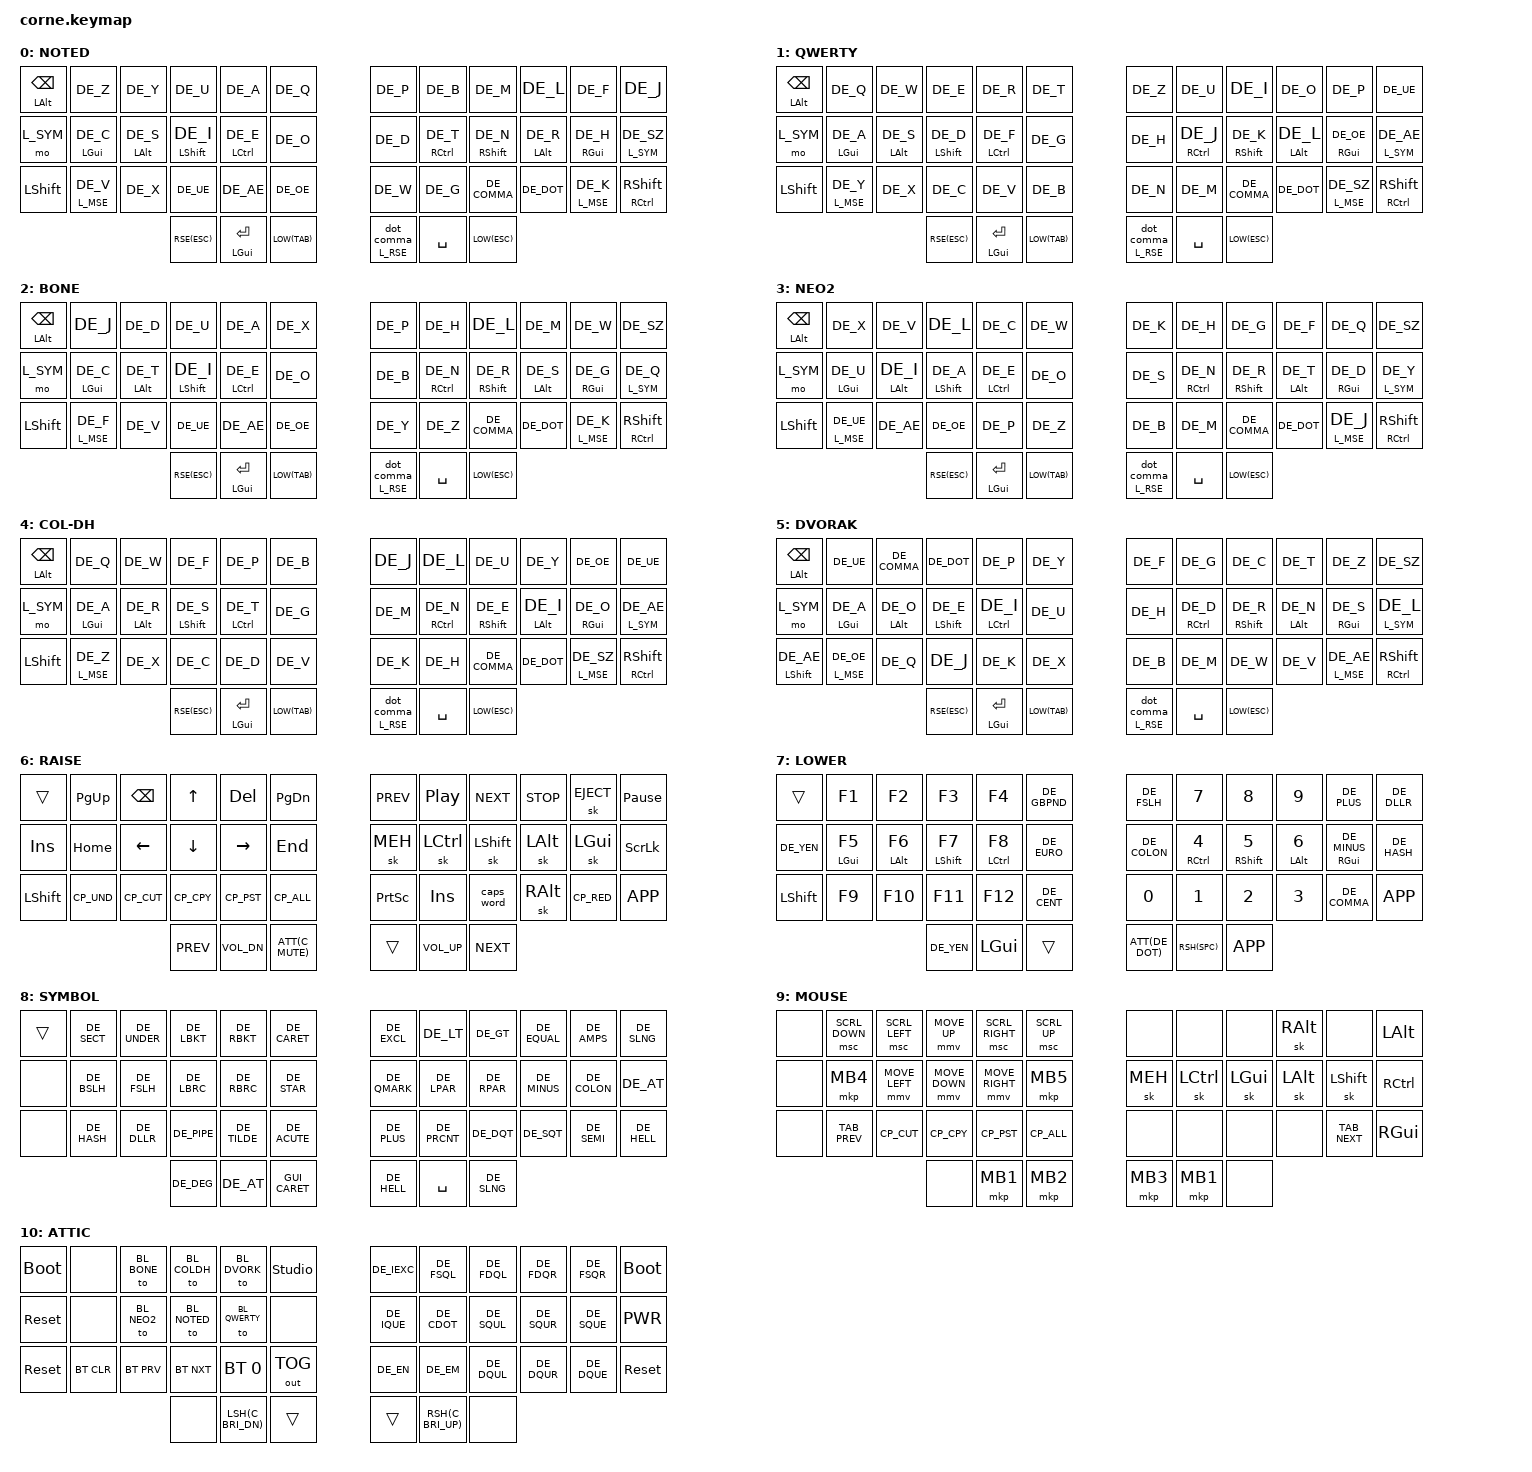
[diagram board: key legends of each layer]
/*
 * Copyright (c) 2020 The ZMK Contributors
 *
 * SPDX-License-Identifier: MIT
 */

// active layers:
#define LAYER_NOTED_ENABLED
#define LAYER_QWERTY_ENABLED
#define LAYER_BONE_ENABLED
#define LAYER_NEO2_ENABLED
#define LAYER_COL_DH_ENABLED
#define LAYER_DVORAK_ENABLED

#include <behaviors.dtsi>
#include <dt-bindings/zmk/keys.h>
#include <dt-bindings/zmk/pointing.h>
#include <dt-bindings/zmk/outputs.h>
#include <dt-bindings/zmk/bt.h>

#include "custom_keys.h"

#include "zmk-helpers/helper.h"
// Source desired key-position labels
#include "zmk-helpers/key-labels/42.h"
#define KEYS_L LT0 LT1 LT2 LT3 LT4     LM0 LM1 LM2 LM3 LM4     LB0 LB1 LB2 LB3 LB4  // Left-hand keys
#define KEYS_R RT0 RT1 RT2 RT3 RT4 RT5 RM0 RM1 RM2 RM3 RM4 RM5 RB0 RB1 RB2 RB3 RB4  // Right-hand keys
#define THUMBS LH2 LH1 LH0 RH0 RH1 RH2                                              // Thumb keys

#define TAPPING_TERM_MS 175
#define QUICK_TAP_MS 125
#define REQUIRE_PRIOR_IDLE_MS 150
/* HRMs left/right */
ZMK_HOLD_TAP(hml,
    flavor = "balanced";
    tapping-term-ms = <TAPPING_TERM_MS>;
    quick-tap-ms = <QUICK_TAP_MS>;
    require-prior-idle-ms = <REQUIRE_PRIOR_IDLE_MS>;
    bindings = <&kp>, <&kp>;
    hold-trigger-key-positions = <KEYS_R THUMBS>;
    hold-trigger-on-release;
)
ZMK_HOLD_TAP(hmr,
    flavor = "balanced";
    tapping-term-ms = <TAPPING_TERM_MS>;
    quick-tap-ms = <QUICK_TAP_MS>;
    require-prior-idle-ms = <REQUIRE_PRIOR_IDLE_MS>;
    bindings = <&kp>, <&kp>;
    hold-trigger-key-positions = <KEYS_L THUMBS>;
    hold-trigger-on-release;
)

/* Symbol layer left/right */
ZMK_HOLD_TAP(lyl,
    flavor = "balanced";
    tapping-term-ms = <TAPPING_TERM_MS>;
    quick-tap-ms = <QUICK_TAP_MS>;
    require-prior-idle-ms = <REQUIRE_PRIOR_IDLE_MS>;
    bindings = <&mo>, <&kp>;
    hold-trigger-key-positions = <KEYS_R THUMBS>;
    hold-trigger-on-release;
)
ZMK_HOLD_TAP(lyr,
    flavor = "balanced";
    tapping-term-ms = <TAPPING_TERM_MS>;
    quick-tap-ms = <QUICK_TAP_MS>;
    require-prior-idle-ms = <REQUIRE_PRIOR_IDLE_MS>;
    bindings = <&mo>, <&kp>;
    hold-trigger-key-positions = <KEYS_L THUMBS>;
    hold-trigger-on-release;
)
/* Hold preferred (for GUI/RET) */
ZMK_HOLD_TAP(hpl,
    flavor = "hold-preferred";
    tapping-term-ms = <TAPPING_TERM_MS>;
    quick-tap-ms = <QUICK_TAP_MS>;
    require-prior-idle-ms = <REQUIRE_PRIOR_IDLE_MS>;
    bindings = <&kp>, <&kp>;
    hold-trigger-key-positions = <KEYS_R THUMBS>;
    hold-trigger-on-release;
)

#define GUI_RET &hpl LGUI RET
#define RSE_DC &rse_dc L_RSE 0

&caps_word {
  continue-list = <DE_AE DE_OE DE_UE DE_SZ DE_MINUS DE_UNDER BACKSPACE DELETE>;
};

/ {
  behaviors {
    // Mod-Morph: Tap = DOT, Shift + Tap = COMMA
    dot_comma: mod_morph_dot_comma {
      compatible = "zmk,behavior-mod-morph";
      label = "Dot and Comma";
      #binding-cells = <0>;
      bindings = <&kp DE_DOT>, <&kp DE_COMMA>;
      mods = <(MOD_LSFT|MOD_RSFT)>;
    };

    // Hold-Tap: Hold = Layer RSE, Tap = Mod-Morph (Dot/Comma)
    rse_dc: hold_tap_dot_comma {
      compatible = "zmk,behavior-hold-tap";
      label = "Hold-Tap Dot and Comma";
      #binding-cells = <2>;
      flavor = "balanced";
      tapping-term-ms = <200>;
      bindings = <&mo>, <&dot_comma>;
    };
  };
  keymap {
    compatible = "zmk,keymap";

#ifdef LAYER_NOTED_ENABLED
base_layer_noted {
  display-name = "NOTED";
  bindings = <
    // ┌─────┬─────┬─────┬─────┬─────┬─────┐   ┌─────┬─────┬─────┬─────┬─────┬─────┐
    // │ BSP │  z  │  y  │  u  │  a  │  q  │   │  p  │  b  │  m  │  l  │  f  │  j  │
    // ├─ALT─┼─────┼─────┼─────┼─────┼─────┤   ├─────┼─────┼─────┼─────┼─────┼─────┤
    // │ SYM │  c  │  s  │  i  │  e  │  o  │   │  d  │  t  │  n  │  r  │  h  │  ß  │
    // ├─────┼─GUI─┼─ALT─┼─SFT─┼─CTL─┼─────┤   ├─────┼─CTL─┼─SFT─┼─ALT─┼─GUI─┼─SYM─┤
    // │ SFT │  v  │  x  │  ü  │  ä  │  ö  │   │  w  │  g  │  ,  │  .  │  k  │ SFT │
    // └─────┴─────┴─────┼─────┼─────┼─────┤   ├─────┼─────┼─────┼─────┴─────┴─CTL─┘
    //                   │ ESC │ ENT │ TAB │   │ ./, │ SPC │ ESC │
    //                   └─RSE─┴─GUI─┴─LWR─┘   └─RSE─┴─────┴─LWR─┘
    &mt LALT BSPC  &kp  DE_Z       &kp  DE_Y      &kp  DE_U       &kp  DE_A       &kp DE_Q       &kp DE_P &kp  DE_B       &kp  DE_M       &kp  DE_L      &kp  DE_F        &kp  DE_J
    &mo L_SYM      &hml LGUI  DE_C &hml LALT DE_S &hml LSHFT DE_I &hml LCTRL DE_E &kp DE_O       &kp DE_D &hmr RCTRL DE_T &hmr RSHFT DE_N &hmr LALT DE_R &hmr RGUI DE_H   &lyr L_SYM DE_SZ
    &kp LSHFT      &lyl L_MSE DE_V &kp  DE_X      &kp  DE_UE      &kp  DE_AE      &kp DE_OE      &kp DE_W &kp  DE_G       &kp  DE_COMMA   &kp  DE_DOT    &lyr L_MSE DE_K  &mt  RCTRL RSHFT
                                                                RSE(ESC)  GUI_RET  LOW(TAB)      RSE_DC  &kp SPACE  LOW(ESC)
  >;
};
#endif // ifdef LAYER_NOTED_ENABLED

#ifdef LAYER_QWERTY_ENABLED
base_layer_qwerty {
  display-name = "QWERTY";
  bindings = <
    // ┌─────┬─────┬─────┬─────┬─────┬─────┐   ┌─────┬─────┬─────┬─────┬─────┬─────┐
    // │ BSP │  q  │  w  │  e  │  r  │  t  │   │  z  │  u  │  i  │  o  │  p  │  ü  │
    // ├─ALT─┼─────┼─────┼─────┼─────┼─────┤   ├─────┼─────┼─────┼─────┼─────┼─────┤
    // │ SYM │  a  │  s  │  d  │  f  │  g  │   │  h  │  j  │  k  │  l  │  ö  │  ä  │
    // ├─────┼─GUI─┼─ALT─┼─SFT─┼─CTL─┼─────┤   ├─────┼─CTL─┼─SFT─┼─ALT─┼─GUI─┼─SYM─┤
    // │ SFT │  y  │  x  │  c  │  v  │  b  │   │  n  │  m  │  ,  │  .  │  ß  │ SFT │
    // └─────┴─────┴─────┼─────┼─────┼─────┤   ├─────┼─────┼─────┼─────┴─────┴─CTL─┘
    //                   │ ESC │ ENT │ TAB │   │ ./, │ SPC │ ESC │
    //                   └─RSE─┴─GUI─┴─LWR─┘   └─RSE─┴─────┴─LWR─┘
    &mt LALT BSPC  &kp  DE_Q       &kp  DE_W      &kp  DE_E       &kp  DE_R       &kp DE_T       &kp DE_Z &kp  DE_U       &kp  DE_I       &kp  DE_O      &kp  DE_P         &kp  DE_UE
    &mo L_SYM      &hml LGUI  DE_A &hml LALT DE_S &hml LSHFT DE_D &hml LCTRL DE_F &kp DE_G       &kp DE_H &hmr RCTRL DE_J &hmr RSHFT DE_K &hmr LALT DE_L &hmr RGUI DE_OE   &lyr L_SYM DE_AE
    &kp LSHFT      &lyl L_MSE DE_Y &kp  DE_X      &kp  DE_C       &kp  DE_V       &kp DE_B       &kp DE_N &kp  DE_M       &kp  DE_COMMA   &kp  DE_DOT    &lyr L_MSE DE_SZ  &mt  RCTRL RSHFT
                                                                RSE(ESC)  GUI_RET  LOW(TAB)      RSE_DC  &kp SPACE  LOW(ESC)
  >;
};
#endif // ifdef LAYER_QWERTY_ENABLED

#ifdef LAYER_BONE_ENABLED
base_layer_bone {
  display-name = "BONE";
  bindings = <
    // ┌─────┬─────┬─────┬─────┬─────┬─────┐   ┌─────┬─────┬─────┬─────┬─────┬─────┐
    // │ BSP │  j  │  d  │  u  │  a  │  x  │   │  p  │  h  │  l  │  m  │  w  │  ß  │
    // ├─ALT─┼─────┼─────┼─────┼─────┼─────┤   ├─────┼─────┼─────┼─────┼─────┼─────┤
    // │ SYM │  c  │  t  │  i  │  e  │  o  │   │  b  │  n  │  r  │  s  │  g  │  q  │
    // ├─────┼─GUI─┼─ALT─┼─SFT─┼─CTL─┼─────┤   ├─────┼─CTL─┼─SFT─┼─ALT─┼─GUI─┼─SYM─┤
    // │ SFT │  f  │  v  │  ü  │  ä  │  ö  │   │  y  │  z  │  ,  │  .  │  k  │ SFT │
    // └─────┴─────┴─────┼─────┼─────┼─────┤   ├─────┼─────┼─────┼─────┴─────┴─CTL─┘
    //                   │ ESC │ ENT │ TAB │   │ ./, │ SPC │ ESC │
    //                   └─RSE─┴─GUI─┴─LWR─┘   └─RSE─┴─────┴─LWR─┘
    &mt LALT BSPC  &kp  DE_J       &kp  DE_D      &kp  DE_U       &kp  DE_A       &kp DE_X       &kp DE_P &kp  DE_H       &kp  DE_L       &kp  DE_M      &kp  DE_W        &kp  DE_SZ
    &mo L_SYM      &hml LGUI  DE_C &hml LALT DE_T &hml LSHFT DE_I &hml LCTRL DE_E &kp DE_O       &kp DE_B &hmr RCTRL DE_N &hmr RSHFT DE_R &hmr LALT DE_S &hmr RGUI DE_G   &lyr L_SYM DE_Q
    &kp LSHFT      &lyl L_MSE DE_F &kp  DE_V      &kp  DE_UE      &kp  DE_AE      &kp DE_OE      &kp DE_Y &kp  DE_Z       &kp  DE_COMMA   &kp  DE_DOT    &lyr L_MSE DE_K  &mt  RCTRL RSHFT
                                                                RSE(ESC)  GUI_RET  LOW(TAB)      RSE_DC  &kp SPACE  LOW(ESC)
  >;
};
#endif // ifdef LAYER_BONE_ENABLED

#ifdef LAYER_NEO2_ENABLED
base_layer_neo2 {
  display-name = "NEO2";
  bindings = <
    // ┌─────┬─────┬─────┬─────┬─────┬─────┐   ┌─────┬─────┬─────┬─────┬─────┬─────┐
    // │ BSP │  x  │  v  │  l  │  c  │  w  │   │  k  │  h  │  g  │  f  │  q  │  ß  │
    // ├─ALT─┼─────┼─────┼─────┼─────┼─────┤   ├─────┼─────┼─────┼─────┼─────┼─────┤
    // │ SYM │  u  │  i  │  a  │  e  │  o  │   │  s  │  n  │  r  │  t  │  d  │  y  │
    // ├─────┼─GUI─┼─ALT─┼─SFT─┼─CTL─┼─────┤   ├─────┼─CTL─┼─SFT─┼─ALT─┼─GUI─┼─SYM─┤
    // │ SFT │  ü  │  ö  │  ä  │  p  │  z  │   │  b  │  m  │  ,  │  .  │  j  │ SFT │
    // └─────┴─────┴─────┼─────┼─────┼─────┤   ├─────┼─────┼─────┼─────┴─────┴─CTL─┘
    //                   │ ESC │ ENT │ TAB │   │ ./, │ SPC │ ESC │
    //                   └─RSE─┴─GUI─┴─LWR─┘   └─RSE─┴─────┴─LWR─┘
    &mt LALT BSPC  &kp  DE_X        &kp  DE_V      &kp  DE_L       &kp  DE_C       &kp DE_W       &kp DE_K &kp  DE_H       &kp  DE_G       &kp  DE_F      &kp  DE_Q        &kp  DE_SZ
    &mo L_SYM      &hml LGUI  DE_U  &hml LALT DE_I &hml LSHFT DE_A &hml LCTRL DE_E &kp DE_O       &kp DE_S &hmr RCTRL DE_N &hmr RSHFT DE_R &hmr LALT DE_T &hmr RGUI  DE_D  &lyr L_SYM DE_Y
    &kp LSHFT      &lyl L_MSE DE_UE &kp  DE_AE     &kp  DE_OE      &kp  DE_P       &kp DE_Z       &kp DE_B &kp  DE_M       &kp  DE_COMMA   &kp  DE_DOT    &lyr L_MSE DE_J  &mt  RCTRL RSHFT
                                                                RSE(ESC)  GUI_RET  LOW(TAB)       RSE_DC  &kp SPACE  LOW(ESC)
  >;
};
#endif // ifdef LAYER_NEO2_ENABLED

#ifdef LAYER_COL_DH_ENABLED
base_layer_colmak {
  display-name = "COL-DH";
  bindings = <
    // ┌─────┬─────┬─────┬─────┬─────┬─────┐   ┌─────┬─────┬─────┬─────┬─────┬─────┐
    // │ BSP │  q  │  w  │  f  │  p  │  b  │   │  j  │  l  │  u  │  y  │  ö  │  ü  │
    // ├─ALT─┼─────┼─────┼─────┼─────┼─────┤   ├─────┼─────┼─────┼─────┼─────┼─────┤
    // │ SYM │  a  │  r  │  s  │  t  │  g  │   │  m  │  n  │  e  │  i  │  o  │  ä  │
    // ├─────┼─GUI─┼─ALT─┼─SFT─┼─CTL─┼─────┤   ├─────┼─CTL─┼─SFT─┼─ALT─┼─GUI─┼─SYM─┤
    // │ SFT │  z  │  x  │  c  │  d  │  v  │   │  k  │  h  │  ,  │  .  │  ß  │ SFT │
    // └─────┴─────┴─────┼─────┼─────┼─────┤   ├─────┼─────┼─────┼─────┴─────┴─CTL─┘
    //                   │ ESC │ ENT │ TAB │   │ ./, │ SPC │ ESC │
    //                   └─RSE─┴─GUI─┴─LWR─┘   └─RSE─┴─────┴─LWR─┘
    &mt LALT BSPC  &kp  DE_Q       &kp  DE_W      &kp  DE_F       &kp  DE_P       &kp DE_B       &kp DE_J &kp  DE_L       &kp  DE_U       &kp  DE_Y      &kp  DE_OE        &kp  DE_UE
    &mo L_SYM      &hml LGUI  DE_A &hml LALT DE_R &hml LSHFT DE_S &hml LCTRL DE_T &kp DE_G       &kp DE_M &hmr RCTRL DE_N &hmr RSHFT DE_E &hmr LALT DE_I &hmr RGUI DE_O    &lyr L_SYM DE_AE
    &kp LSHFT      &lyl L_MSE DE_Z &kp  DE_X      &kp  DE_C       &kp  DE_D       &kp DE_V       &kp DE_K &kp  DE_H       &kp  DE_COMMA   &kp  DE_DOT    &lyr L_MSE DE_SZ  &mt  RCTRL RSHFT
                                                                RSE(ESC)  GUI_RET  LOW(TAB)      RSE_DC  &kp SPACE  LOW(ESC)
  >;
};
#endif // ifdef LAYER_COL_DH_ENABLED

#ifdef LAYER_DVORAK_ENABLED
base_layer_dvorak {
  display-name = "DVORAK";
  bindings = <
    // ┌─────┬─────┬─────┬─────┬─────┬─────┐   ┌─────┬─────┬─────┬─────┬─────┬─────┐
    // │ BSP │  ü  │  ,  │  .  │  p  │  y  │   │  f  │  g  │  c  │  t  │  z  │  ß  │
    // ├─ALT─┼─────┼─────┼─────┼─────┼─────┤   ├─────┼─────┼─────┼─────┼─────┼─────┤
    // │ SYM │  a  │  o  │  e  │  i  │  u  │   │  h  │  d  │  r  │  n  │  s  │  l  │
    // ├─────┼─GUI─┼─ALT─┼─SFT─┼─CTL─┼─────┤   ├─────┼─CTL─┼─SFT─┼─ALT─┼─GUI─┼─SYM─┤
    // │  ä  │  ö  │  q  │  j  │  k  │  x  │   │  b  │  m  │  w  │  v  │  ä  │ SFT │
    // └─SFT─┴─────┴─────┼─────┼─────┼─────┤   ├─────┼─────┼─────┼─────┴─────┴─CTL─┘
    //                   │ ESC │ ENT │ TAB │   │ ./, │ SPC │ ESC │
    //                   └─RSE─┴─GUI─┴─LWR─┘   └─RSE─┴─────┴─LWR─┘
    &mt LALT BSPC   &kp  DE_UE       &kp  DE_COMMA  &kp  DE_DOT     &kp  DE_P       &kp DE_Y       &kp DE_F &kp  DE_G       &kp  DE_C       &kp  DE_T      &kp  DE_Z         &kp  DE_SZ
    &mo L_SYM       &hml LGUI  DE_A  &hml LALT DE_O &hml LSHFT DE_E &hml LCTRL DE_I &kp DE_U       &kp DE_H &hmr RCTRL DE_D &hmr RSHFT DE_R &hmr LALT DE_N &hmr RGUI DE_S    &lyr L_SYM DE_L
    &mt LSHFT DE_AE &lyl L_MSE DE_OE &kp  DE_Q      &kp  DE_J       &kp  DE_K       &kp DE_X       &kp DE_B &kp  DE_M       &kp  DE_W       &kp  DE_V      &lyr L_MSE DE_AE  &mt  RCTRL RSHFT
                                                                RSE(ESC)  GUI_RET  LOW(TAB)        RSE_DC  &kp SPACE  LOW(ESC)
  >;
};
#endif // ifdef LAYER_DVORAK_ENABLED

raise_layer {
  display-name = "RAISE";
  bindings = <
    // ┌─────┬─────┬─────┬─────┬─────┬─────┐   ┌─────┬─────┬─────┬─────┬─────┬─────┐
    // │ BSP │ PUp │ BSP │ Up  │ Del │ PDn │   │ Prv │ Ply │ Nxt │ Stp │ Ejt │ Pse │
    // ├─ALT─┼─────┼─────┼─────┼─────┼─────┤   ├─────┼─────┼─────┼─────┼─────┼─────┤
    // │ Ins │ Hme │ Lft │ Dwn │ Rgt │ End │   │ Meh*│ Ctl*│ Sft*│ Alt*│ Gui*│ SLk │
    // ├─────┼─────┼─────┼─────┼─────┼─────┤   ├─────┼─────┼─────┼─────┼─────┼─────┤
    // │ SFT │ Udo │ Cut │ Cpy │ Pst │ SAl │   │ PSc │ Ins │ CpW │ AGr*│ Rdo │ APP │
    // └─────┴─────┴─────┼─────┼─────┼─────┤   ├─────┼─────┼─────┼─────┴─────┴─────┘
    //                   │ Prv │ V - │ Mte │   │ (x) │ V + │ Nxt │
    //                   └─────┴─────┴─────┘   └─────┴─────┴─────┘
    &trans     &kp PG_UP  &kp BSPC   &kp UP     &kp DEL    &kp PG_DN       &kp C_PREV  &kp C_PP   &kp C_NEXT &kp C_STOP &sk C_EJECT  &kp PAUSE_BREAK
    &kp INS    &kp HOME   &kp LEFT   &kp DOWN   &kp RIGHT  &kp END         &sk MEH     &sk LCTRL  &sk LSHFT  &sk LALT   &sk LGUI     &kp SLCK
    &kp LSHFT  &kp CP_UND &kp CP_CUT &kp CP_CPY &kp CP_PST &kp CP_ALL      &kp PSCRN   &kp INS    &caps_word &sk RALT   &kp CP_RED   &kp K_APP
                                   &kp C_PREV  &kp C_VOL_DN   ATT(C_MUTE)  &trans  &kp C_VOL_UP  &kp C_NEXT
  >;
};

lower_layer {
  display-name = "LOWER";
  bindings = <
    // ┌─────┬─────┬─────┬─────┬─────┬─────┐   ┌─────┬─────┬─────┬─────┬─────┬─────┐
    // │ ___ │ F1  │ F2  │ F3  │ F4  │  £  │   │  /  │  7  │  8  │  9  │  +  │  $  │
    // ├─────┼─────┼─────┼─────┼─────┼─────┤   ├─────┼─────┼─────┼─────┼─────┼─────┤
    // │  ¥  │ F5  │ F6  │ F7  │ F8  │  €  │   │  :  │  4  │  5  │  6  │  -  │  #  │
    // ├─────┼─────┼─────┼─────┼─────┼─────┤   ├─────┼─CTL─┼─SFT─┼─ALT─┼─GUI─┼─────┤
    // │ SFT │ F9  │ F10 │ F11 │ F12 │  ¢  │   │  0  │  1  │  2  │  3  │  ,  │ APP │
    // └─────┴─────┴─────┼─────┼─────┼─────┤   ├─────┼─────┼─────┼─────┴─────┴─────┘
    //                   │  ¥  │ GUI │ (x) │   │  .  │ SPC │ APP │
    //                   └─────┴─────┴─────┘   └─────┴─SFT─┴─────┘
    &trans      &kp F1       &kp F2        &kp F3         &kp F4         &kp DE_GBPND    &kp DE_FSLH  &kp  N7       &kp  N8       &kp  N9      &kp  DE_PLUS        &kp DE_DLLR
    &kp DE_YEN  &hmr LGUI F5 &hmr LALT F6  &hmr LSHFT F7  &hmr LCTRL F8  &kp DE_EURO     &kp DE_COLON &hmr RCTRL N4 &hmr RSHFT N5 &hmr LALT N6 &hmr RGUI DE_MINUS  &kp DE_HASH
    &kp LSHFT   &kp F9       &kp F10       &kp F11        &kp F12        &kp DE_CENT     &kp N0       &kp  N1       &kp  N2       &kp  N3      &kp  DE_COMMA       &kp K_APP
                                                        &kp DE_YEN  &kp LGUI  &trans     ATT(DE_DOT)  RSH(SPC)  &kp K_APP
  >;
};

symbol_layer {
  display-name = "SYMBOL";
  // ┌─────┬─────┬─────┬─────┬─────┬─────┐   ┌─────┬─────┬─────┬─────┬─────┬─────┐
  // │     │  §  │  _  │  [  │  ]  │  ^  │   │  !  │  <  │  >  │  =  │  &  │  ſ  │
  // ├─────┼─────┼─────┼─────┼─────┼─────┤   ├─────┼─────┼─────┼─────┼─────┼─────┤
  // │     │  \  │  /  │  {  │  }  │  *  │   │  ?  │  (  │  )  │  -  │  :  │  @  │
  // ├─────┼─────┼─────┼─────┼─────┼─────┤   ├─────┼─────┼─────┼─────┼─────┼─────┤
  // │     │  #  │  $  │ "|" │  ~  │  ´  │   │  +  │  %  │  "  │  '  │  ;  │  …  │
  // └─────┴─────┴─────┼─────┼─────┼─────┤   ├─────┼─────┼─────┼─────┴─────┴─────┘
  //                   │  °  │  @  │ G+ˇ │   │  …  │ SPC │  ſ  │
  //                   └─────┴─────┴─────┘   └─────┴─────┴─────┘
  bindings = <
    &trans  &kp DE_SECT  &kp DE_UNDER &kp DE_LBKT  &kp DE_RBKT  &kp DE_CARET       &kp DE_EXCL  &kp DE_LT    &kp DE_GT    &kp DE_EQUAL &kp DE_AMPS   &kp DE_SLNG
    &none   &kp DE_BSLH  &kp DE_FSLH  &kp DE_LBRC  &kp DE_RBRC  &kp DE_STAR        &kp DE_QMARK &kp DE_LPAR  &kp DE_RPAR  &kp DE_MINUS &kp DE_COLON  &kp DE_AT
    &none   &kp DE_HASH  &kp DE_DLLR  &kp DE_PIPE  &kp DE_TILDE &kp DE_ACUTE       &kp DE_PLUS  &kp DE_PRCNT &kp DE_DQT   &kp DE_SQT   &kp DE_SEMI   &kp DE_HELL
                                            &kp DE_DEG  &kp DE_AT  GUI_CARET       &kp DE_HELL  &kp SPACE  &kp DE_SLNG
  >;
};

mouse_layer {
  display-name = "MOUSE";
  // ┌─────┬─────┬─────┬─────┬─────┬─────┐   ┌─────┬─────┬─────┬─────┬─────┬─────┐
  // │     │ MW↓ │ MW← │ Ms↑ │ MW→ │ MW↑ │   │     │     │     │     │     │ ALT │
  // ├─────┼─────┼─────┼─────┼─────┼─────┤   ├─────┼─────┼─────┼─────┼─────┼─────┤
  // │     │ MB4 │ Ms← │ Ms↓ │ Ms→ │ MB5 │   │ Meh │ Ctl │ Gui │ Alt │ Sft │ CTL │
  // ├─────┼─────┼─────┼─────┼─────┼─────┤   ├─────┼─────┼─────┼─────┼─────┼─────┤
  // │     │ Tb← │ Cut │ Cpy │ Pst │ All │   │     │     │     │ AGr │ Tb→ │ GUI │
  // └─────┴─────┴─────┼─────┼─────┼─────┤   ├─────┼─────┼─────┼─────┴─────┴─────┘
  //                   │     │ MB1 │ MB2 │   │ MB3 │ MB1 │     │
  //                   └─────┴─────┴─────┘   └─────┴─────┴─────┘
  bindings = <
    &none      &msc SCRL_DOWN &msc SCRL_LEFT &mmv MOVE_UP   &msc SCRL_RIGHT &msc SCRL_UP     &none   &none     &none    &sk RALT &none     &kp LALT
    &none      &mkp MB4       &mmv MOVE_LEFT &mmv MOVE_DOWN &mmv MOVE_RIGHT &mkp MB5         &sk MEH &sk LCTRL &sk LGUI &sk LALT &sk LSHFT &kp RCTRL
    &none      TAB_PREV       &kp  CP_CUT    &kp  CP_CPY    &kp  CP_PST     &kp  CP_ALL      &none   &none     &none    &none    TAB_NEXT  &kp RGUI
                                                           &none  &mkp MB1  &mkp MB2         &mkp MB3  &mkp MB1  &none
  >;
};

attic_layer {
  display-name = "ATTIC";
  bindings = <
    // ┌─────┬─────┬─────┬─────┬─────┬─────┐   ┌─────┬─────┬─────┬─────┬─────┬─────┐
    // │ BtL │     │ BONE│COLDH│DVORK│ StL │   │  ¡  │  ‹  │  «  │  »  │  ›  │ BtL │
    // ├─────┼─────┼─────┼─────┼─────┼─────┤   ├─────┼─────┼─────┼─────┼─────┼─────┤
    // │ Rst │     │ NEO │NOTED│QWERT│     │   │  ¿  │  •  │  ‚  │  ‘  │  ’  │ Pwr │
    // ├─────┼─────┼─────┼─────┼─────┼─────┤   ├─────┼─────┼─────┼─────┼─────┼─────┤
    // │ Rst │ BCl │ BT↓ │ BT↑ │ BT0 │ OuT │   │ n-– │ m-— │  „  │  “  │  ”  │ Rst │
    // └─────┴─────┴─────┼─────┼─────┼─────┤   ├─────┼─────┼─────┼─────┴─────┴─────┘
    //                   │ OuT │ Br- │ (x) │   │ (x) │ Br+ │     │
    //                   └─────┴─────┴─────┘   └─────┴─────┴─────┘
    &bootloader    &none          &to BL_BONE &to BL_COLDH &to BL_DVORK  &studio_unlock    &kp DE_IEXC &kp DE_FSQL &kp DE_FDQL &kp DE_FDQR &kp DE_FSQR  &bootloader
    &sys_reset     &none          &to BL_NEO2 &to BL_NOTED &to BL_QWERTY &none             &kp DE_IQUE &kp DE_CDOT &kp DE_SQUL &kp DE_SQUR &kp DE_SQUE  &kp C_PWR
    &sys_reset     &bt BT_CLR     &bt BT_PRV  &bt BT_NXT   &bt BT_SEL 0  &out OUT_TOG      &kp DE_EN   &kp DE_EM   &kp DE_DQUL &kp DE_DQUR &kp DE_DQUE  &sys_reset
                                                         &none  LSH(C_BRI_DN)   &trans     &trans  RSH(C_BRI_UP)  &none
  >;
};

// --(layer template)------------------------------------------------------------------
//                 some_layer {
  //                         display-name = "";
  //                         bindings = <
    // // ┌─────┬─────┬─────┬─────┬─────┬─────┐   ┌─────┬─────┬─────┬─────┬─────┬─────┐
    // // │     │     │     │     │     │     │   │     │     │     │     │     │     │
    // // ├─────┼─────┼─────┼─────┼─────┼─────┤   ├─────┼─────┼─────┼─────┼─────┼─────┤
    // // │     │     │     │     │     │     │   │     │     │     │     │     │     │
    // // ├─────┼─────┼─────┼─────┼─────┼─────┤   ├─────┼─────┼─────┼─────┼─────┼─────┤
    // // │     │     │     │     │     │     │   │     │     │     │     │     │     │
    // // └─────┴─────┴─────┼─────┼─────┼─────┤   ├─────┼─────┼─────┼─────┴─────┴─────┘
    // //                   │     │     │     │   │     │     │     │
    // //                   └─────┴─────┴─────┘   └─────┴─────┴─────┘
    //    &trans  &none &none &none &none &none      &none &none &none &none &none  &none
    //    &none  &none &none &none &none &none      &none &none &none &none &none  &none
    //    &none  &none &none &none &none &none      &none &none &none &none &none  &none
    //                       &none  &none  &none  &none  &none  &none
    //                         >;
    //                 };
    };
};

